# nrf7140_wificore register map
Vendor: Nordic Semiconductor; Series: nRF71; File version: 1
Registers are 32-bit, read-write, reset 0x0 unless marked. A register's access mark holds for its fields unless they carry their own. Offsets are from the block's base; [hi:lo] are bit positions; lines under a group give offsets from that group; {n}, {i} and the like mark numbered series; 'fields as' and 'values as' point back to an identical list; <NAME> marks a mode.

## RPUPHY (part 5 of 8) — WIFICore RPU PHY peripherals
Base 0x48080000; alternate view of RPUMAC
0xD000 WLAN_RTM_TD group — Unspecified
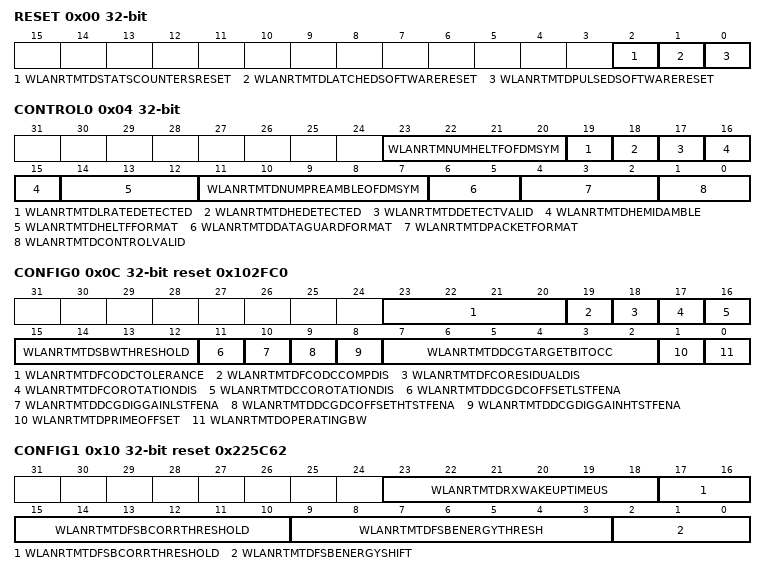
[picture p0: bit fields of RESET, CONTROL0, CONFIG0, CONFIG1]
  0x00 RESET — WLAN RTM TD RESET
    [2] WLANRTMTDSTATSCOUNTERSRESET — Self-clearing software reset for the statistics counters.
    [1] WLANRTMTDLATCHEDSOFTWARERESET — Latched software reset.
    [0] WLANRTMTDPULSEDSOFTWARERESET — Self-clearing software reset.
  0x04 CONTROL0 — WLAN RTM TD CONTROL 0
    [23:20] WLANRTMNUMHELTFOFDMSYM — Number of HE-LTF OFDM symbols in the preamble section (do NOT include the midables HE-LTFs)Note: default value set when software reset
    [19] WLANRTMTDLRATEDETECTED — L-SIG 6 Mbps detection flag :Note: default value set when software reset
      0=LSigRateNot6Mbps; 1=LSigRateIs6Mbps
    [18] WLANRTMTDHEDETECTED — HE detection flag :Note: default value set when software reset
      0=NonHeDetected; 1=HeDetected
    [17] WLANRTMTDDETECTVALID — Indicates the detection control register fields are valid.Note: default value set when software reset
      0=Detection control register fields not yet set; 1=WLAN_RTM_TD_HE_DETECTED and WLAN_RTM_TD_LRATE_DETECTED are valid
    [16:15] WLANRTMTDHEMIDAMBLE — Midambles configuration :Note: default value set when software reset
      0=NoMidambles; 1=Reserve (This is reserved.); 2=Midambles every 10 OFDM data symbols,; 3=Midambles every 20 OFDM data symbols
    [14:12] WLANRTMTDHELTFFORMAT — HE-LTF format :0: 1x HE-LTF (3.2us)+ 0.8us GI,1: 1x HE-LTF (3.2us)+ 1.6us GI,2: 2x HE-LTF (6.4us)+ 0.8us GI,3: 2x HE-LTF (6.4us)+ 1.6us GI,4: 4x HE-LTF (12.8us) + 0.8us GI,5: 4x HE-LTF (12.8us) + 3.2us GI,6-7: ReservedNote: default value set when software reset
    [11:7] WLANRTMTDNUMPREAMBLEOFDMSYM — Number of preamble / header OFDM symbols, counting after L-SIG (i.e. for legacy packet the value is zero)Note: default value set when software reset
    [6:5] WLANRTMTDDATAGUARDFORMAT — Guard duration for DATA symbols :
      0=04UsLegacyShort; 1=08UsLegacyLong; 2=16Us; 3=32Us
    [4:2] WLANRTMTDPACKETFORMAT — Packet format:Note: default value set when software reset
      0=LLegacy; 1=Ht; 2=Reserve (This is reserved.); 3=Vht; 4=HeSu; 5=HeMu; 6=HeEr; 7=HeTb
    [1:0] WLANRTMTDCONTROLVALID — Indicates the control registers WLAN_RTM_TD_CONTROL_0 and WLAN_RTM_TD_CONTROL_1 are valid.Note: default value set when software reset
      0=Control registers not yet set; 1=Only WLAN_RTM_TD_PACKET_FORMAT is valid; 2=Legacy fields decoding control registers are valid; 3=All the control registers are valid
  0x08 CONTROL1 — WLAN RTM TD CONTROL 1
    [23:0] WLANRTMTDNUMDATAOFDMSYM — Number of data and midamble (HE only) OFDM symbols. Considered valid if WLAN_RTM_TD_CONTROL_VALID is 2 or 3.Note: default value set when software reset
  0x0C CONFIG0 reset 0x102FC0 — WLAN RTM TD CONFIG 0
    [23:20] WLANRTMTDFCODCTOLERANCE — ?? Tolerance for the FCO-DC estimation calculation (u-8.12).
    [19] WLANRTMTDFCODCCOMPDIS — Disable / enable fine DC offset compensation in FCO.
    [18] WLANRTMTDFCORESIDUALDIS — Disable / enable residual frequency offset correction.
    [17] WLANRTMTDFCOROTATIONDIS — Disable / enable fine carrier frequency offset correction.
    [16] WLANRTMTDCCOROTATIONDIS — Disable / enable coarse carrier frequency offset correction.
    [15:12] WLANRTMTDSBWTHRESHOLD — Signal bandwidth detection threshold (u4.0).
    [11] WLANRTMTDDCGDCOFFSETLSTFENA — Enable / disable DC offset compensation for L-STF.
    [10] WLANRTMTDDCGDIGGAINLSTFENA — Enable / disable digital gain compensation for L-STF.
    [9] WLANRTMTDDCGDCOFFSETHTSTFENA — Enable / disable DC offset compensation for HT-STF/VHT-STF/HE-STF (2nd AGC enabled).
    [8] WLANRTMTDDCGDIGGAINHTSTFENA — Enable / disable digital gain compensation for HT-STF/VHT-STF/HE-STF (2nd AGC enabled).
    [7:2] WLANRTMTDDCGTARGETBITOCC — Digital gain target bit occupancy in dB (u6.0).Default value corresponds to 12 bits SCP (full scale) and 18 dB headroom.
    [1] WLANRTMTDPRIMEOFFSET — Prime offset for 40 MHz operating bandwidth:
      0=Low; 1=High
    [0] WLANRTMTDOPERATINGBW — Receiver operating bandwidth:
      0=20Mhz; 1=40Mhz
  0x10 CONFIG1 reset 0x225C62 — WLAN RTM TD CONFIG 1
    [23:18] WLANRTMTDRXWAKEUPTIMEUS — Standby to Active time in us (u4.2).Note: Used to enable RX prior to expiry of the packet duration counter when Power Save mode is active.
    [17:10] WLANRTMTDFSBCORRTHRESHOLD — Fine symbol boundary energy correlation threshold ratio (u0.8).
    [9:3] WLANRTMTDFSBENERGYTHRESH — Fine symbol boundary peak detection threshold ratio (u0.7).
    [2:0] WLANRTMTDFSBENERGYSHIFT — Fine symbol boundary energy scale shift (u3.0).
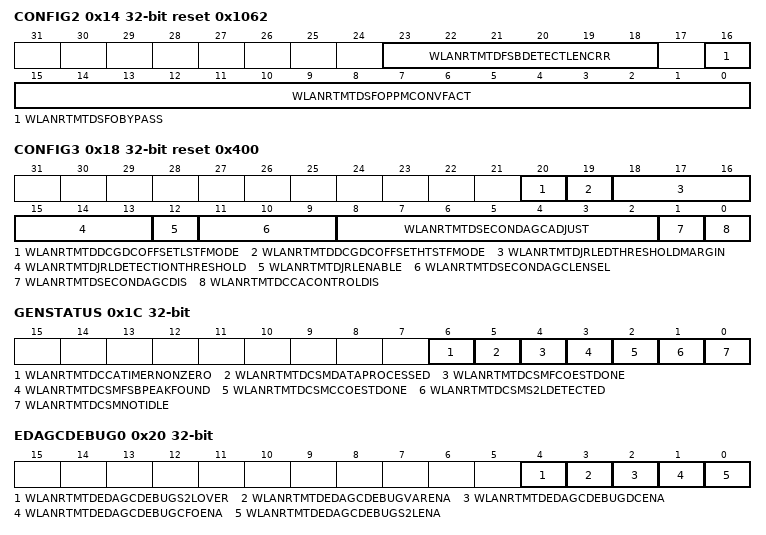
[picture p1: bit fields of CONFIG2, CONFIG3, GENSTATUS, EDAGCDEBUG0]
  0x14 CONFIG2 reset 0x1062 — WLAN RTM TD CONFIG 2
    [23:18] WLANRTMTDFSBDETECTLENCRR — Fine symbol boundary detection length correction factor (s5.0).
    [16] WLANRTMTDSFOBYPASS — Bypass Sample Frequency Offset when set to 1
    [15:0] WLANRTMTDSFOPPMCONVFACT — Sampling Frequency Offset, time tracking conversion factor: value of [resampler factor] * OpBW/fc,where OpBw is the operating bandwidth and fc is the channel centre frequency. (u-4.20)Note: default value set for resampler factor = 1, OpBW = 20MHz and fc = 5GHz
  0x18 CONFIG3 reset 0x400 — WLAN RTM TD CONFIG 3
    [20] WLANRTMTDDCGDCOFFSETLSTFMODE — 0: DC offset compensation for L-STF based on RTM-DCG DC estimation.1: DC offset compensation for L-STF based on ED DC estimation.
    [19] WLANRTMTDDCGDCOFFSETHTSTFMODE — 0: DC offset compensation for HT-STF/VHT-STF/HE-STF based on RTM-DCG DC estimation (2nd AGC enabled).1: DC offset compensation for HT-STF/VHT-STF/HE-STF based on ED DC estimation.
    [18:16] WLANRTMTDJRLEDTHRESHOLDMARGIN — Headroom added to the minimum variance for OFDM correlation once Jammer signal is detected in dB (u3.0).
    [15:13] WLANRTMTDJRLDETECTIONTHRESHOLD — Jammer Detection Threshold. Total number of s2lFails required to trigger Jammer detection - 1 (u3.0).
    [12] WLANRTMTDJRLENABLE — Enable/disable Jammer Rejection Logic : ED threshold and minimum variance for OFDM correlation PASS increased toED RSSI snapshot + EdThresholdMargin when Jammer is detected.
    [11:9] WLANRTMTDSECONDAGCLENSEL — Second AGC estimation window length selection: ceil(log2(0.8*Fs)) - 3, where Fs is the ADC sampling rate.Note: default value is set assuming Fs equals 40MHz
    [8:2] WLANRTMTDSECONDAGCADJUST — Second AGC start wait time adjustment in number of samples. (s6.0)
    [1] WLANRTMTDSECONDAGCDIS — Disable / enable AGC control for the second estimation (ED/AGC).
    [0] WLANRTMTDCCACONTROLDIS — Disable / enable CCA control for correlation indication and status known (ED).Timer non-zero flag always zero when disabled.
  0x1C GENSTATUS ro — WLAN RTM TD GEN STATUS
    [6] WLANRTMTDCCATIMERNONZERO — CCA timer non-zero
    [5] WLANRTMTDCSMDATAPROCESSED — Indicates all the OFDM symbols are output to the FFT
    [4] WLANRTMTDCSMFCOESTDONE — Indicates the fine frequency offset is estimated
    [3] WLANRTMTDCSMFSBPEAKFOUND — Indicates the FSB index is calculated : LTF correlation
    [2] WLANRTMTDCSMCCOESTDONE — Indicates the coarse frequency offset is estimated
    [1] WLANRTMTDCSMS2LDETECTED — Indicates the S2L event is asserted by the ED
    [0] WLANRTMTDCSMNOTIDLE — Indicates the training mode - time domain is not idle (i.e. processing packet)
  0x20 EDAGCDEBUG0 — WLAN RTM TD EDAGC DEBUG 0
    [4] WLANRTMTDEDAGCDEBUGS2LOVER — S2LOver flag emulation : overwrites input signal cin_s2l_over_event.
    [3] WLANRTMTDEDAGCDEBUGVARENA — Enable/disable ED-AGC debug support : ED-AGC prime variance signals from registers WLAN_RTM_TD_EDAGC_PRIME20_VAR/WLAN_RTM_TD_EDAGC_PRIME40_VAR.
    [2] WLANRTMTDEDAGCDEBUGDCENA — Enable/disable ED-AGC debug support : ED-AGC DC signals from registers WLAN_RTM_TD_EDAGCDC_S2L_RE/WLAN_RTM_TD_EDAGCDC_S2L_IM and WLAN_RTM_TD_EDAGCDC_2ND_RE/WLAN_RTM_TD_EDAGCDC_2ND_IM.
    [1] WLANRTMTDEDAGCDEBUGCFOENA — Enable/disable ED-AGC debug support : ED-AGC CFO signals from registers WLAN_RTM_TD_EDAGC_CFO_RE/WLAN_RTM_TD_EDAGC_CFO_IM.
    [0] WLANRTMTDEDAGCDEBUGS2LENA — Enable/disable ED-AGC debug support : ED-AGC S2L-over signal from register WLAN_RTM_TD_EDAGC_DEBUG_S2LOVER.
  0x24 EDAGCDEBUG1 — WLAN RTM TD EDAGC DEBUG 1
    [23:0] WLANRTMTDEDAGCCFORE — ED CFO emulation : overwrites input signal cin_edagccfo_re (s0.23).
  0x28 EDAGCDEBUG2 — WLAN RTM TD EDAGC DEBUG 2
    [23:0] WLANRTMTDEDAGCCFOIM — ED CFO emulation : overwrites input signal cin_edagccfo_im (s0.23).
  0x2C EDAGCDEBUG3 — WLAN RTM TD EDAGC DEBUG 3
    [19:0] WLANRTMTDEDAGCPRIME20VAR — ED Prime20 variance emulation : overwrites input signal cin_edprime20_var (u20.0).
  0x30 EDAGCDEBUG4 — WLAN RTM TD EDAGC DEBUG 4
    [19:0] WLANRTMTDEDAGCPRIME40VAR — ED Prime20 variance emulation : overwrites input signal cin_edprime40_var (u20.0).
  0x34 DCGSTATUS0 ro — WLAN RTM TD DCG STATUS 0
    [23:0] WLANRTMTDDCGDCOFFSETLSTF — DC offset estimation for L-STF - complex (s-1.12).
  0x38 DCGSTATUS1 ro — WLAN RTM TD DCG STATUS 1
    [8:0] WLANRTMTDDCGDIGITALGAINLSTFDB — Digital gain estimation for L-STF in dBs (s6.2).
  0x3C DCGSTATUS2 ro — WLAN RTM TD DCG STATUS 2
    [23:0] WLANRTMTDDCGDCOFFSETHTSTF — DC offset estimation for HT-STF/VHT-STF/HE-STF - complex (s-1.12).
  0x40 DCGSTATUS3 ro — WLAN RTM TD DCG STATUS 3
    [8:0] WLANRTMTDDCGDIGITALGAINHTSTFDB — Digital gain estimation for HT-STF/VHT-STF/HE-STF in dBs (s6.2).
  0x44 CFOSTATUS0 ro — WLAN RTM TD CFO STATUS 0
    [15:0] WLANRTMTDCCOFREQUENCYOFFSET — Coarse frequency offset estimation (s-5.20).
  0x48 CFOSTATUS1 ro — WLAN RTM TD CFO STATUS 1
    [15:0] WLANRTMTDFCOFREQUENCYOFFSET — Fine frequency offset estimation (s-5.20).
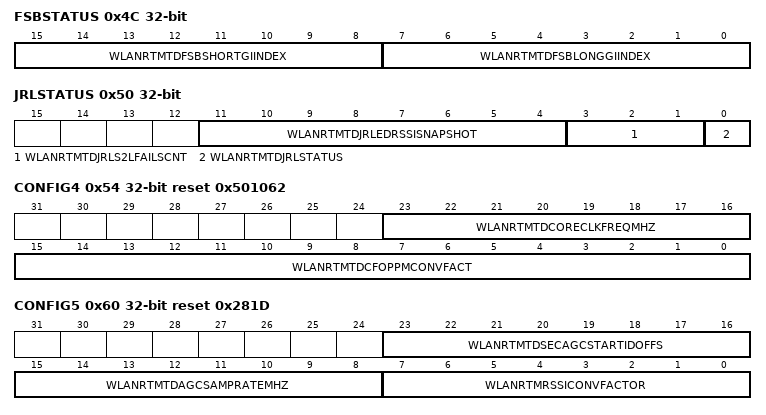
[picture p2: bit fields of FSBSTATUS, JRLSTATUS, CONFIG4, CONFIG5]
  0x4C FSBSTATUS ro — WLAN RTM TD FSB STATUS
    [15:8] WLANRTMTDFSBSHORTGIINDEX — FSB index for the short guard interval (s7.0).
    [7:0] WLANRTMTDFSBLONGGIINDEX — FSB index for the long guard interval (s7.0).
  0x50 JRLSTATUS ro — WLAN RTM TD JRL STATUS
    [11:4] WLANRTMTDJRLEDRSSISNAPSHOT — ED RSSI (in dBm) snapshot taken after the latest ED-done event.
    [3:1] WLANRTMTDJRLS2LFAILSCNT — Consecutive number of S2L fails after every ED.
    [0] WLANRTMTDJRLSTATUS — Jammer detection status (cleared on low energy detection):
      0=no Jammer has been detected; 1=Jammer has been detected (number of consecutive S2L fails equals JRL_DETECTION_THRESHOLD)
  0x54 CONFIG4 reset 0x501062 — WLAN RTM TD CONFIG 4
    [23:16] WLANRTMTDCORECLKFREQMHZ — Core clock frequency in MHz. (u8.0)
    [15:0] WLANRTMTDCFOPPMCONVFACT — Carrier Frequency Offset, to PPM conversion factor: value of OpBW/fc,where OpBw is the operating bandwidth and fc is the channel centre frequency. (u-4.20)Note: default value set for OpBW = 20MHz and fc = 5GHz
  0x58 STATSCOUNTER0 — WLAN RTM TD STATS COUNTER 0
    [23:0] WLANRTMLOWENERGYEVENTCOUNT — Number of low energy events detected.
  0x5C STATSCOUNTER1 — WLAN RTM TD STATS COUNTER 1
    [23:0] WLANRTMPOPEVENTCOUNT — Number of packet-over-packet events detected.
  0x60 CONFIG5 reset 0x281D — WLAN RTM TD CONFIG 5
    [23:16] WLANRTMTDSECAGCSTARTIDOFFS — Second AGC start ID offset (at AGC sampling rate). (s7.0)
    [15:8] WLANRTMTDAGCSAMPRATEMHZ — AGC sampling rate MHz. (u8.0)
    [7:0] WLANRTMRSSICONVFACTOR — The LTF-RSSI conversion factor. s7.0This factor represents the conversion from voltage domain (power in dBm) in analog to digital representation of IQ's.LTF_RSSI_DBM = LTF_POWER_DB - AGC_GAIN_DB - DGC_GAIN_DB - WLAN_RTM_RSSI_CONV_FACTOR
  0x64 RSSISTATUS ro — WLAN RTM TD RSSI STATUS
    [7:0] WLANRTMTDRSSILTFDBM — The RSSI computation of HT-LTF/VHT-LTF/HE-LTF is an indicative of the DATA field power in dBm.
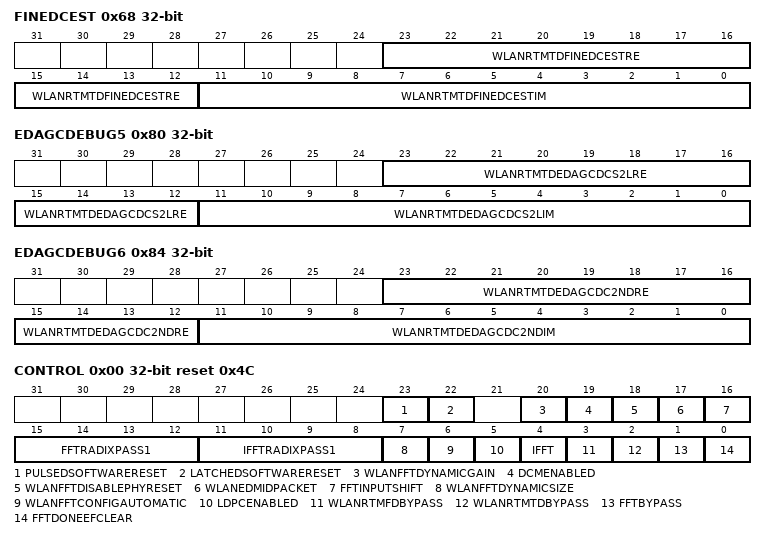
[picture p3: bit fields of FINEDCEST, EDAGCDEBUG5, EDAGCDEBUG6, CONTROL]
  0x68 FINEDCEST ro — WLAN RTM TD FINE DC EST
    [23:12] WLANRTMTDFINEDCESTRE — Fine DC estimation real part S-1.12.
    [11:0] WLANRTMTDFINEDCESTIM — Fine DC estimation imaginary part S-1.12.
  0x6C STATSCOUNTER2 — WLAN RTM TD STATS COUNTER 2
    [23:0] WLANRTMMIDPACKETDETECTCOUNT — Number of mid-packet detected.
  0x70 DEBUGGING — WLAN RTM TD DEBUG
    [1:0] WLANRTMTDDEBUG — Enable debug registers WLAN_RTM_TD_DEBUG_VALID and WLAN_RTM_TD_DEBUG_ENABLE
      0=Disabled; 1=ValidEnable; 2=Sticky(Valid), Sticky(Enable); 3=Valid & Enable, Sticky(Valid & Enable)
  0x74 DEBUGVALID ro — WLAN RTM TD DEBUG VALID
    [19:0] WLANRTMTDDEBUGVALID — Live state of the valid flow control signals0: valid_up_l1: valid_dw_l2: dcg_valid_up3: dcg_fco_valid_up4: dcg_valid_dw5: atn_valid_up6: atn_valid_dw7: cco_valid_up8: cco_valid_dw9: cco_atn_valid10: atn_cco_valid11: fsb_valid_up12: fsb_valid_dw13: fco_valid_up14: fco_valid_dw15: fco_atn_valid16: atn_fco_valid17: rsd_atn_valid18: sbw_valid_up19: sbw_valid_dw
  0x78 DEBUGENABLE ro — WLAN RTM TD DEBUG ENABLE
    [19:0] WLANRTMTDDEBUGENABLE — Live state of the enable flow control signals0: enable_up_l1: enable_dw_l2: dcg_enable_up3: dcg_fco_enable_up4: dcg_enable_dw5: atn_enable_up6: atn_enable_dw7: cco_enable_up8: cco_enable_dw9: cco_atn_enable10: atn_cco_enable11: fsb_enable_up12: fsb_enable_dw13: fco_enable_up14: fco_enable_dw15: fco_atn_enable16: atn_fco_enable17: rsd_atn_enable18: sbw_enable_up19: sbw_enable_dw
  0x7C CONTROL2 — WLAN RTM TD CONTROL 2
    [1:0] WLANRTMTDSCOCCUPANCYLEVEL — Sub-carriers occupancy level:0: High : >= 81.25 percent of sub-carriers in a OFDM symbol are used1: Mid: >= 20.3125 percent of sub-carriers in a OFDM symbol are used2: Low: <20.3125 percent of sub-carriersin a OFDM symbolare usedConsidered valid if WLAN_RTM_TD_CONTROL_VALID is 3.Note: default value set when software reset
  0x80 EDAGCDEBUG5 — WLAN RTM TD EDAGC DEBUG 5
    [23:12] WLANRTMTDEDAGCDCS2LRE — ED DC estimation emulation : overwrites input signal cin_edagcdc_s2l_re (s-1.12).
    [11:0] WLANRTMTDEDAGCDCS2LIM — ED DC estimation emulation : overwrites input signal cin_edagcdc_s2l_im (s-1.12).
  0x84 EDAGCDEBUG6 — WLAN RTM TD EDAGC DEBUG 6
    [23:12] WLANRTMTDEDAGCDC2NDRE — ED DC estimation emulation : overwrites input signal cin_edagcdc_2nd_re (s-1.12).
    [11:0] WLANRTMTDEDAGCDC2NDIM — ED DC estimation emulation : overwrites input signal cin_edagcdc_2nd_im (s-1.12).
0xF000 WLAN_FFT group — Unspecified
  0x00 CONTROL reset 0x4C — WLAN FFT CONTROL
    [23] PULSEDSOFTWARERESET — 0 : Do nothing1 : Apply a pulsed software resetThis bit is automatically returns to 0
    [22] LATCHEDSOFTWARERESET
      0=RemoveReset; 1=ApplyReset
    [20] WLANFFTDYNAMICGAIN — Dynamic FFT gain (stages shift values):
      0=FFT gain configured by the WLAN_FFT_SHIFT_VALUES registers; 1=FFT gain configured by sideband signal
    [19] DCMENABLED
      0=DCM decoding is disabled; 1=DcmDecodingIsEnabled
    [18] WLANFFTDISABLEPHYRESET — Disable automatic PHY reset.
      0=PHY will automatically reset; 1=PHY will not automatically reset
    [17] WLANEDMIDPACKET — Mid-packet energy detection flag:
      0=DSSS or OFDM packet detected; 1=MidPacketDetected
    [16] FFTINPUTSHIFT — 0 : No data shift at the input of the FFT engine.Input to FFT engine is in [0..N-1] order, where N is size of FFT.1 : Data at the input of the FFT engine is shifted such that thesecond half of input vector is swapped with the first half.Input to FFT engine is in [N/2..N-1,0,..N/2-1] order.
    [15:12] FFTRADIXPASS1 — Select the radix used on the first FFT pass.Options are0-5 : reserved6 : radix=647 : radix=1288 : radix=2569 : radix=51210-15 : reserved
    [11:8] IFFTRADIXPASS1 — Select the radix used on the first IFFT pass.Options are0-5 : reserved6 : radix=647 : radix=1288 : radix=2569 : radix=51210-15 : reserved
    [7] WLANFFTDYNAMICSIZE — Dynamic FFT size enable.
      0=FFT size configured by the FFT_RADIX_PASS1/IFFT_RADIX_PASS1 registers; 1=FFT size configured by sideband signal
    [6] WLANFFTCONFIGAUTOMATIC — Enable automatic configuration of the WLAN_FFT.
      0=Manual configuration mode; 1=Automatic configuration mode
    [5] LDPCENABLED
      0=LDPC decoding is disabled; 1=LDPC decoding is enabled
    [4] IFFT
      0=PerformFftOperation; 1=PerformIfftOperation
    [3] WLANRTMFDBYPASS — Set the Receiver Training Mode - Frequency Domain in bypass:Note: The RTM-FD is set in bypass when FFT_BYPASS is 1.
      0=Do not bypass Rx Training Mode Time Domain; 1=Bypass Rx Training Mode Time Domain
    [2] WLANRTMTDBYPASS — Set the Receiver Training Mode - Time Domain in bypass:
      values as WLANRTMFDBYPASS
    [1] FFTBYPASS
      0=Perform FFT/IFFT operation; 1=Bypass
    [0] FFTDONEEFCLEAR — 0 : Do nothing1 : Clear the event flag WLAN_FFT_DONE_EF_STATUSThis bit automatically returns to 0
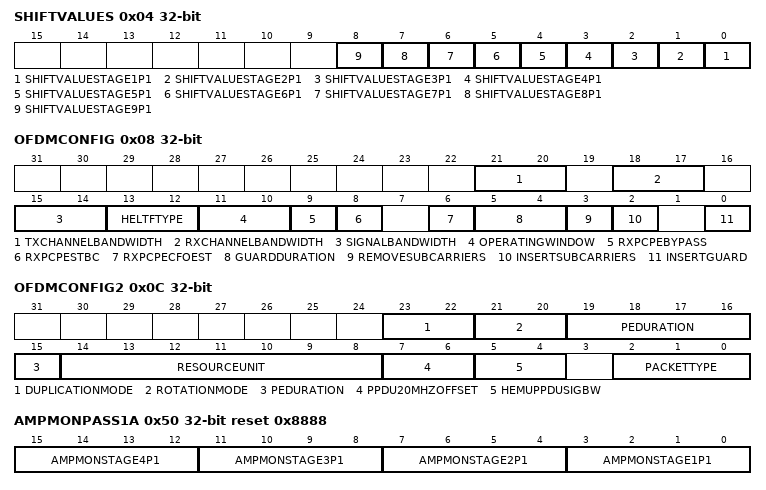
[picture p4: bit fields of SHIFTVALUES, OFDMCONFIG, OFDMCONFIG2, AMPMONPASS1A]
  0x04 SHIFTVALUES — WLAN FFT SHIFT VALUES
    [n-1] SHIFTVALUESTAGE{n}P1 (n=1..9) — SHIFT SELECT for Pass 1 / Stage {n}.Options are as above
  0x08 OFDMCONFIG — WLAN FFT OFDM CONFIG
    [21:20] TXCHANNELBANDWIDTH — Selects the channel bandwidth
      0=20Mhz; 1=40Mhz; 2=80Mhz; 3=Reserve (This is reserved.)
    [18:17] RXCHANNELBANDWIDTH — Selects the channel bandwidth
      0=20Mhz; 1=40Mhz; 2=80Mhz; 3=Reserve (This is reserved.)
    [15:14] SIGNALBANDWIDTH — Selects the signal bandwidth0 : 20MHz1 : 40MHz2 : 80MHz3 : reservedMust be equal or less than CHANNEL_BANDWIDTH.For receive, see the OPERATING_WINDOW description.For transmit, when signal bandwidth is less than channel bandwidth, input OFDM symbol will be duplicatedbefore performing inverse FFT. If channel bandwidth is two times signal bandwidth then OFDM symbol will beduplicated and if channel bandwidth is four times signal bandwidth then OFDM symbol will be quadrupled.
    [13:12] HELTFTYPE — Type of HE-LTF preamble. For HE formats only.
      0=1XHeLtf; 1=2XHeLtf; 2=4XHeLtf
    [11:10] OPERATINGWINDOW — For receive selects the operating window when the channel bandwidth is not equal to the signal bandwidth0 : -3 Most lower operating window1 : -1 Lower operating window2 : +1 Upper operating window3 : +3 Most upper operating windowWhen the channel bandwidth is 40MHz and the signal bandwidth is 20MHz, the operating window should be configured toeither value 1 (lower operating window) or 2 (upper operating window). When the channel bandwidth is 80MHz and the signalbandwidth is 20MHz, the operating window should be configured to either value 1, 2, 3, or 4. 80MHz cbw/ 40MHz sbwshould follow the first case.
    [9] RXPCPEBYPASS — CPE compensation control.0 : CPE compensation1 : BypassThis field is used when REMOVE_SUB_CARRIERS is active (RX mode).In both cases pilots will be discarded but when bypass is not activeCPE compensation will be performed.
    [8] RXPCPESTBC — Selects STBC mode. HT-packets only.
      0=NonStbc; 1=Stbc
    [6] RXPCPECFOEST — When set enables the CFO estimation based on the CPE.
    [5:4] GUARDDURATION — Specifies the guard duration to be inserted or removed:
      0=04Us; 1=08Us; 2=16Us; 3=32Us
    [3] REMOVESUBCARRIERS — 0: Do nothing1: For receive, remove the null sub-carriers from the FFT output data stream.Pilots will be outputted first following by data sub-carriers.
    [2] INSERTSUBCARRIERS
      0=DoNothing; 1=For transmit, insert null sub-carriers into the FFT input data stream
    [0] INSERTGUARD
      0=DoNothing; 1=For transmit, insert Guard to the FFT output data stream
  0x0C OFDMCONFIG2 — WLAN FFT OFDM CONFIG 2
    [23:22] DUPLICATIONMODE
      0=NoDuplication; 1=OFDM symbol duplicated prior to IFFT; 2=OFDM symbol quadrupled prior to IFFT
    [21:20] ROTATIONMODE
      0=NoRotation; 1=Rotation by gamma factor for 40MHz signal bandwidth; 2=RotationByGammaFacto2 (Rotation by gamma factor for 80MHz signal bandwidth)
    [19:15] PEDURATION — Duration of Packet Extension in microseconds. Only applicable for HE packets.
    [14:8] RESOURCEUNIT — Used to determine the positions of pilot and null sub-carriers.Valid range of values for SIGNAL_BANDWIDTH = 20 MHz are [0-8, 37-40, 53-54, 61].Valid range of values for SIGNAL_BANDWIDTH = 40 MHz are [0-17, 37-44, 53-56, 61-62, 65].Only applicable for HE packets.(SIGNAL_BANDWIDTH in WLAN_FFT_OFDM_CONFIG register)
    [7:6] PPDU20MHZOFFSET — Selects the 20MHz partition of the PPDU bandwidth (up to 80 MHz supported):0-1: when BSS operating bandwidth is 40 MHz0-3: when BSS operating bandwidth is 80 MHzNOTE: only used when HE-MU packet and HEMU_PPDU_SIGBW >= 40 MHz
    [5:4] HEMUPPDUSIGBW — Operating BW of the BSS (Basic Service Set):NOTE: only used for HE-MU packets
      0=20Mhz; 1=40Mhz; 2=80Mhz; 3=Reserve (This is reserved.)
    [2:0] PACKETTYPE — Selects packet type:0 : Legacy1 : HT-MF2 : HT-GF3 : VHT4 : HE-SU5 : HE-MU6 : HE-ER7 : HE-TBPackets 0-3 (Legacy, HT_MF, HT_GF, VHT) are in Pre-HE group with OFDM symbol length of 3.2us.HE packet has 12.8us OFDM symbol length.NOTE: Whenever packet_type is configured the initial state of scrambler will be set accordingly.Scrambler is used within CPE block to generate PN sequence for pilot sign generation. PN sequencehas 127 elements and cyclically repeats after 127 OFDM symbols.
  {0x10+4j} RXPCPECHSTREAM1PILOT[{j}] (j=0..7) — Description collection: WLAN FFT RXP CPE CH STREAM1 PILOT
    [23:0] RXPCPECHSTREAM1PILOT — Channel estimate for stream 1 on the pilot subcarrier.
  {0x30+4j} RXPCPECHSTREAM2PILOT[{j}] (j=0..7) — Description collection: WLAN FFT RXP CPE CH STREAM2 PILOT
    [23:0] RXPCPECHSTREAM2PILOT — Channel estimate for stream 2 on the pilot subcarrier.
  0x50 AMPMONPASS1A ro reset 0x8888 — WLAN FFT AMP MON PASS1A
    [15:12] AMPMONSTAGE4P1 — Amplitude Monitor - Pass 1 Stage 415 : full_scale14 : 3 dB below full scale13 : 6 dB below full scale..8 : 21 dB below full scale0-7 : reserved
    [11:8] AMPMONSTAGE3P1 — Amplitude Monitor - Pass 1 Stage 3 : format as above
    [7:4] AMPMONSTAGE2P1 — Amplitude Monitor - Pass 1 Stage 2 : format as above
    [3:0] AMPMONSTAGE1P1 — Amplitude Monitor - Pass 1 Stage 1 : format as above
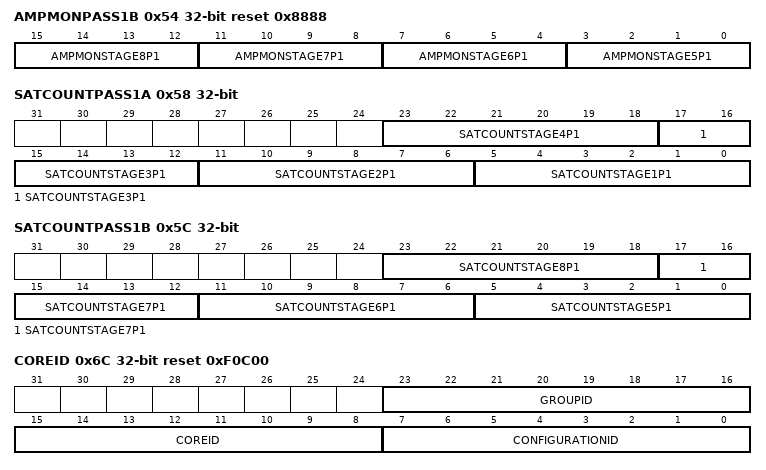
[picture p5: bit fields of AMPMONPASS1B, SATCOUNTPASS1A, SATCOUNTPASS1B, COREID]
  0x54 AMPMONPASS1B ro reset 0x8888 — WLAN FFT AMP MON PASS1B
    [15:12] AMPMONSTAGE8P1 — Amplitude Monitor - Pass 1 Stage 815 : full_scale14 : 3 dB below full scale13 : 6 dB below full scale..8 : 21 dB below full scale0-7 : reserved
    [11:8] AMPMONSTAGE7P1 — Amplitude Monitor - Pass 1 Stage 7 : format as above
    [7:4] AMPMONSTAGE6P1 — Amplitude Monitor - Pass 1 Stage 6 : format as above
    [3:0] AMPMONSTAGE5P1 — Amplitude Monitor - Pass 1 Stage 5 : format as above
  0x58 SATCOUNTPASS1A ro — WLAN FFT SAT COUNT PASS1A
    [6n-1:6n-6] SATCOUNTSTAGE{n}P1 (n=1..4) — Number of saturations in pass1 stage {n}
  0x5C SATCOUNTPASS1B ro — WLAN FFT SAT COUNT PASS1B
    [6n-25:6n-30] SATCOUNTSTAGE{n}P1 (n=5..8) — Number of saturations in pass1 stage {n}
  0x60 STATUS ro — WLAN FFT STATUS
    [0] FFTDONEEFSTATUS — FFT_DONE_EF_STATUS is set to 1 when an FFT operation completes,and is cleared when 1 is written to FFT_DONE_EF_CLEAR in the WLAN_FFT_CONTROL register.
  0x64 FINALSHIFTVALUE — WLAN FFT FINAL SHIFT VALUE
    [4:0] FINALSHIFTVALUE — Signed 2's compliment shift value to be applied after the final stage of an FFT.
  0x68 MAXRADIX ro reset 0x100 — WLAN FFT MAX RADIX
    [10:0] MAXRADIX — MAX RADIX for FFT Engine
  0x6C COREID ro reset 0xF0C00 — WLAN FFT CORE ID
    [23:16] GROUPID — Identifies core as part of an IMG IP family group. [0x0F = UCC]
    [15:8] COREID — Identifies the member of the IP group. [0x0C = FFT]
    [7:0] CONFIGURATIONID — Configuration of the core.
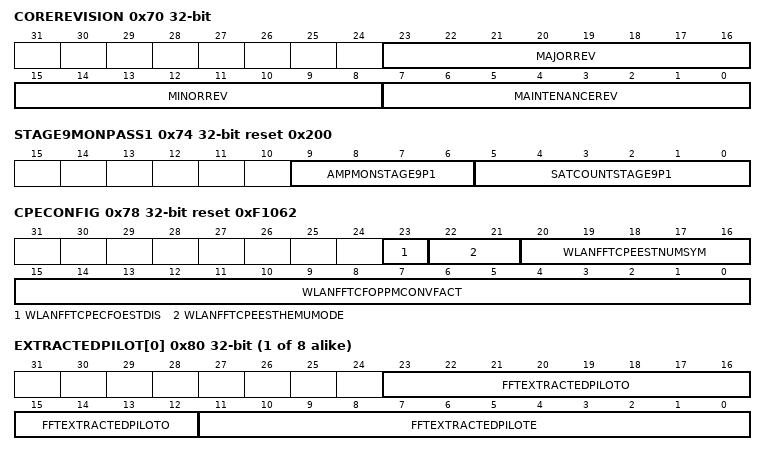
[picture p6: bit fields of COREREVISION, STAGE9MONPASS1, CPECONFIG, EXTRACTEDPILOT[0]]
  0x70 COREREVISION ro — WLAN FFT CORE REVISION
    [23:16] MAJORREV — Family Major Release Revision.
    [15:8] MINORREV — Core Minor Release Revision.
    [7:0] MAINTENANCEREV — Maintenance Release Revision.
  0x74 STAGE9MONPASS1 ro reset 0x200 — WLAN FFT STAGE9 MON PASS1
    [9:6] AMPMONSTAGE9P1 — Amplitude Monitor - Pass 1 Stage 9
    [5:0] SATCOUNTSTAGE9P1 — Number of saturations in pass1 stage 9
  0x78 CPECONFIG reset 0xF1062 — WLAN FFT CPE CONFIG
    [23] WLANFFTCPECFOESTDIS — Disable the CFO estimation based on the CPE : ignore RXP_CPE_CFO_EST field
    [22:21] WLANFFTCPEESTHEMUMODE — CPE based frequency offset estimation mode for HE-MU packets:
      0=Use HE-SIG-B and Data symbols CPE estimations (final HE-SIG-B in ppm is sum to the Data ppm estimations); 1=Use HE-SIG-B symbols CPE estimations only; 2=Use Data symbols CPE estimations only (if there is only one data Symbol then the HE-SIG-B is used)
    [20:16] WLANFFTCPEESTNUMSYM — Number of CPE estimations used for the CPE based frequency offset estimation.
    [15:0] WLANFFTCFOPPMCONVFACT — Carrier Frequency Offset, to PPM conversion factor: value of OpBW/fc,where OpBw is the operating bandwidth and fc is the channel centre frequency. (u-4.20)Note: default value set for OpBW = 20MHz and fc = 5GHz
  0x7C CPESTATUS ro — WLAN FFT CPE STATUS
    [15:0] WLANFFTCPEFREQUENCYOFFSET — CPE based frequency offset estimation (s-5.20).
  {0x80+4j} EXTRACTEDPILOT[{j}] (j=0..7) ro — Description collection: WLAN FFT EXTRACTED PILOT
    [23:12] FFTEXTRACTEDPILOTO — FFT_EXTRACTED_PILOT_O is updated on every odd pilot extracted from FFT output stream.The 6 MSBs of the real and imaginary part are stored.
    [11:0] FFTEXTRACTEDPILOTE — FFT_EXTRACTED_PILOT_E is updated on every even pilot extracted from FFT output stream.The 6 MSBs of the real and imaginary part are stored.
  0xA0 MCSCONFIG — WLAN FFT MCS CONFIG
    [23:20] MCSVALUE — Modulation and coding scheme
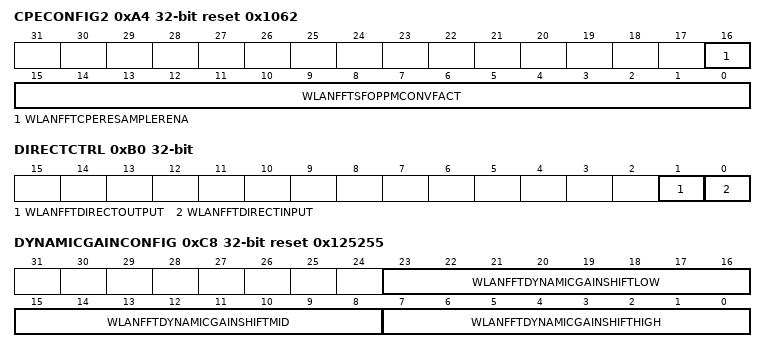
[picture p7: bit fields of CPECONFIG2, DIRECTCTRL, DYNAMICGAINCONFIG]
  0xA4 CPECONFIG2 reset 0x1062 — WLAN FFT CPE CONFIG 2
    [16] WLANFFTCPERESAMPLERENA — Enable CPE estimation based SFO error update to the SCP resampler.
    [15:0] WLANFFTSFOPPMCONVFACT — Sampling Frequency Offset, time tracking conversion factor: value of [resampler factor] * OpBW/fc,where OpBw is the operating bandwidth and fc is the channel centre frequency. (u-4.20)Note: default value set for resampler factor = 1, OpBW = 20MHz and fc = 5GHz
  0xA8 CPECONFIG3 — WLAN FFT CPE CONFIG 3
    [3:0] WLANRXPCPEFIELD — Selects packet type:0: LSIG (L)1: LDATA (L)2: HTSIG (L)3: HTDATA (HT)4: VHTSIGA (L)5: VHTSIGB (HT)6: VHTDATA (VHT)7: RLSIG (L)8: HESIGA_SU (HT)9: HESIGA_X (HT)10 : HESIGA_ER (HT)11 : HESIGA_MU (HT)12 : HESIGB (VHT)13 : HEDATA_SU (HE)14 : HEDATA_ER (HE)15 : HEDATA_MU (HE)Packet types 0-3 (Legacy, HT_MF, HT_GF, VHT) are in Pre-HE group with OFDM symbol length of 3.2us.HE packet has 12.8us OFDM symbol length.NOTE: Whenever field is configured the initial state of scrambler will be set accordingly.Scrambler is used within CPE block to generate PN sequence for pilot sign generation. PN sequencehas 127 elements and cyclically repeats after 127 OFDM symbols.
  0xAC TBUSRDMODE — WLAN FFT TBUS RD MODE
    [1] WLANFFTTBUSRDDISCARD — Discard PBus debug mode output (WLAN_FFT_TBUS_RD_MODE=1):
      0=Output to PBus (debug mode); 1=DiscardOutput
  0xB0 DIRECTCTRL — WLAN FFT DIRECT CTRL
    [1] WLANFFTDIRECTOUTPUT — Selects whether TXP output goes to next pipeline stage or EDC (tbus).
      0=Tbus; 1=Direct
    [0] WLANFFTDIRECTINPUT — Selects whether TXP input comes from previous pipeline stage or EDC (tbus).
      0=Tbus; 1=Direct
  0xB4 STARTINGSTSNUM — WLAN FFT STARTING STS NUM
    [1:0] STARTINGSTSNUM — Starting STS num for cyclic shift delay
      0=0; 1=2X; 2=1X; 3=3X
  0xB8 TBUSRDSIGNATURE ro reset 0xFFFFFF — WLAN FFT TBUS RD SIGNATURE
    [23:0] WLANFFTTBUSRDSIGNATURE — TBus debug output data signature.
  0xBC DEBUGGING — WLAN FFT DEBUG
    [1:0] WLANFFTDEBUG — Enable debug registers WLAN_FFT_DEBUG_VALID and WLAN_FFT_DEBUG_ENABLE
      values as WLAN_RTM_TD.DEBUGGING.WLANRTMTDDEBUG
  0xC0 DEBUGVALID ro — WLAN FFT DEBUG VALID
    [17:0] WLANFFTDEBUGVALID — Live state of the valid flow control signals0: FFT WR1: Unused - Tied to 02: Unused - Tied to 03: Null SC Insertion Input4: Null SC Insertion Output5: FFT Input FIFO Input6: FFT Input FIFO Output7: Engine Input8: Engine Output9: RTM FFT Input10: RTM FFT Output11: FFT Output FIFO Input12: FFT Output FIFO Output13: Raw FFT Output14: Unused - Tied to 015: Unused - Tied to 016: Unused - Tied to 017: FFT RD
  0xC4 DEBUGENABLE ro — WLAN FFT DEBUG ENABLE
    [17:0] WLANFFTDEBUGENABLE — Live state of the enable flow control signals0: FFT WR1: Unused - Tied to 02: Unused - Tied to 03: Null SC Insertion Input4: Null SC Insertion Output5: FFT Input FIFO Input6: FFT Input FIFO Output7: Engine Input8: Engine Output9: RTM FFT Input10: RTM FFT Output11: FFT Output FIFO Input12: FFT Output FIFO Output13: Raw FFT Output14: Unused - Tied to 015: Unused - Tied to 016: Unused - Tied to 017: FFT RD
  0xC8 DYNAMICGAINCONFIG reset 0x125255 — WLAN FFT DYNAMIC GAIN CONFIG
    [23:16] WLANFFTDYNAMICGAINSHIFTLOW — FFT gain configuration (shift values) when WLAN_FFT_DYNAMIC_GAIN is set and SC occupancy is Low
    [15:8] WLANFFTDYNAMICGAINSHIFTMID — FFT gain configuration (shift values) when WLAN_FFT_DYNAMIC_GAIN is set and SC occupancy is Mid
    [7:0] WLANFFTDYNAMICGAINSHIFTHIGH — FFT gain configuration (shift values) when WLAN_FFT_DYNAMIC_GAIN is set and SC occupancy is High
  0xCC IGNOREWRSYNC — WLAN FFT IGNORE WR SYNC
    [0] WLANFFTIGNOREWRSYNC
